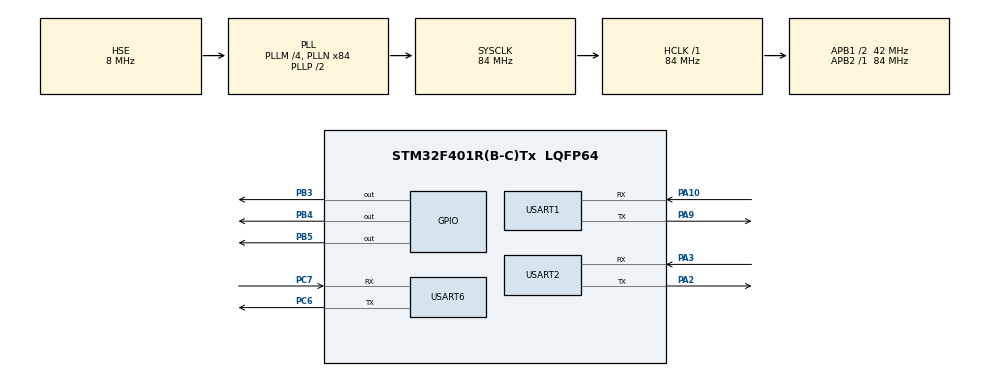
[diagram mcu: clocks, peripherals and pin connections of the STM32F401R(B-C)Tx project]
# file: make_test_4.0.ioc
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Dma.Request0=USART2_RX
Dma.Request1=USART2_TX
Dma.Request2=USART1_RX
Dma.Request3=USART1_TX
Dma.Request4=USART6_RX
Dma.Request5=USART6_TX
Dma.USART1_RX.2.Direction=DMA_PERIPH_TO_MEMORY
Dma.USART1_RX.2.FIFOMode=DMA_FIFOMODE_DISABLE
Dma.USART1_RX.2.Instance=DMA2_Stream2
Dma.USART1_RX.2.MemDataAlignment=DMA_MDATAALIGN_BYTE
Dma.USART1_RX.2.MemInc=DMA_MINC_ENABLE
Dma.USART1_RX.2.Mode=DMA_NORMAL
Dma.USART1_RX.2.PeriphDataAlignment=DMA_PDATAALIGN_BYTE
Dma.USART1_RX.2.PeriphInc=DMA_PINC_DISABLE
Dma.USART1_RX.2.Priority=DMA_PRIORITY_LOW
Dma.USART1_TX.3.Direction=DMA_MEMORY_TO_PERIPH
Dma.USART1_TX.3.FIFOMode=DMA_FIFOMODE_DISABLE
Dma.USART1_TX.3.Instance=DMA2_Stream7
Dma.USART1_TX.3.MemDataAlignment=DMA_MDATAALIGN_BYTE
Dma.USART1_TX.3.MemInc=DMA_MINC_ENABLE
Dma.USART1_TX.3.Mode=DMA_NORMAL
Dma.USART1_TX.3.PeriphDataAlignment=DMA_PDATAALIGN_BYTE
Dma.USART1_TX.3.PeriphInc=DMA_PINC_DISABLE
Dma.USART1_TX.3.Priority=DMA_PRIORITY_LOW
Dma.USART2_RX.0.Direction=DMA_PERIPH_TO_MEMORY
Dma.USART2_RX.0.FIFOMode=DMA_FIFOMODE_DISABLE
Dma.USART2_RX.0.Instance=DMA1_Stream5
Dma.USART2_RX.0.MemDataAlignment=DMA_MDATAALIGN_BYTE
Dma.USART2_RX.0.MemInc=DMA_MINC_ENABLE
Dma.USART2_RX.0.Mode=DMA_NORMAL
Dma.USART2_RX.0.PeriphDataAlignment=DMA_PDATAALIGN_BYTE
Dma.USART2_RX.0.PeriphInc=DMA_PINC_DISABLE
Dma.USART2_RX.0.Priority=DMA_PRIORITY_LOW
Dma.USART2_TX.1.Direction=DMA_MEMORY_TO_PERIPH
Dma.USART2_TX.1.FIFOMode=DMA_FIFOMODE_DISABLE
Dma.USART2_TX.1.Instance=DMA1_Stream6
Dma.USART2_TX.1.MemDataAlignment=DMA_MDATAALIGN_BYTE
Dma.USART2_TX.1.MemInc=DMA_MINC_ENABLE
Dma.USART2_TX.1.Mode=DMA_NORMAL
Dma.USART2_TX.1.PeriphDataAlignment=DMA_PDATAALIGN_BYTE
Dma.USART2_TX.1.PeriphInc=DMA_PINC_DISABLE
Dma.USART2_TX.1.Priority=DMA_PRIORITY_LOW
Dma.USART6_RX.4.Direction=DMA_PERIPH_TO_MEMORY
Dma.USART6_RX.4.FIFOMode=DMA_FIFOMODE_DISABLE
Dma.USART6_RX.4.Instance=DMA2_Stream1
Dma.USART6_RX.4.MemDataAlignment=DMA_MDATAALIGN_BYTE
Dma.USART6_RX.4.MemInc=DMA_MINC_ENABLE
Dma.USART6_RX.4.Mode=DMA_NORMAL
Dma.USART6_RX.4.PeriphDataAlignment=DMA_PDATAALIGN_BYTE
Dma.USART6_RX.4.PeriphInc=DMA_PINC_DISABLE
Dma.USART6_RX.4.Priority=DMA_PRIORITY_LOW
Dma.USART6_TX.5.Direction=DMA_MEMORY_TO_PERIPH
Dma.USART6_TX.5.FIFOMode=DMA_FIFOMODE_DISABLE
Dma.USART6_TX.5.Instance=DMA2_Stream6
Dma.USART6_TX.5.MemDataAlignment=DMA_MDATAALIGN_BYTE
Dma.USART6_TX.5.MemInc=DMA_MINC_ENABLE
Dma.USART6_TX.5.Mode=DMA_NORMAL
Dma.USART6_TX.5.PeriphDataAlignment=DMA_PDATAALIGN_BYTE
Dma.USART6_TX.5.PeriphInc=DMA_PINC_DISABLE
Dma.USART6_TX.5.Priority=DMA_PRIORITY_LOW
Mcu.Family=STM32F4
Mcu.Name=STM32F401R(B-C)Tx
Mcu.Package=LQFP64
NVIC.DMA1_Stream5_IRQn=true\:0\:0\:false\:false\:true\:false\:true
NVIC.DMA1_Stream6_IRQn=true\:0\:0\:false\:false\:true\:false\:true
NVIC.DMA2_Stream1_IRQn=true\:0\:0\:false\:false\:true\:false\:true
NVIC.DMA2_Stream2_IRQn=true\:0\:0\:false\:false\:true\:false\:true
NVIC.DMA2_Stream6_IRQn=true\:0\:0\:false\:false\:true\:false\:true
NVIC.DMA2_Stream7_IRQn=true\:0\:0\:false\:false\:true\:false\:true
NVIC.PriorityGroup=NVIC_PRIORITYGROUP_4
NVIC.USART1_IRQn=true\:0\:0\:false\:false\:false\:true\:true
NVIC.USART2_IRQn=true\:0\:0\:false\:false\:false\:true\:true
NVIC.USART6_IRQn=true\:0\:0\:false\:false\:false\:true\:true
PA10.Mode=Asynchronous
PA10.Signal=USART1_RX
PA2.Mode=Asynchronous
PA2.Signal=USART2_TX
PA3.Mode=Asynchronous
PA3.Signal=USART2_RX
PA9.Mode=Asynchronous
PA9.Signal=USART1_TX
PB3.PinState=GPIO_PIN_SET
PB3.Signal=GPIO_Output
PB4.PinState=GPIO_PIN_SET
PB4.Signal=GPIO_Output
PB5.PinState=GPIO_PIN_SET
PB5.Signal=GPIO_Output
PC14-OSC32_IN.Mode=LSE-External-Oscillator
PC14-OSC32_IN.Signal=RCC_OSC32_IN
PC15-OSC32_OUT.Mode=LSE-External-Oscillator
PC15-OSC32_OUT.Signal=RCC_OSC32_OUT
PC6.Mode=Asynchronous
PC6.Signal=USART6_TX
PC7.Mode=Asynchronous
PC7.Signal=USART6_RX
PH0\ -\ OSC_IN.Mode=HSE-External-Oscillator
PH0\ -\ OSC_IN.Signal=RCC_OSC_IN
PH1\ -\ OSC_OUT.Mode=HSE-External-Oscillator
PH1\ -\ OSC_OUT.Signal=RCC_OSC_OUT
ProjectManager.HeapSize=0x200
ProjectManager.StackSize=0x400
ProjectManager.TargetToolchain=Makefile
RCC.48MHZClocksFreq_Value=42000000
RCC.AHBFreq_Value=84000000
RCC.APB1CLKDivider=RCC_HCLK_DIV2
RCC.APB1Freq_Value=42000000
RCC.APB1TimFreq_Value=84000000
RCC.APB2Freq_Value=84000000
RCC.APB2TimFreq_Value=84000000
RCC.CortexFreq_Value=84000000
RCC.HCLKFreq_Value=84000000
RCC.HSE_VALUE=8000000
RCC.HSI_VALUE=16000000
RCC.PLLM=4
RCC.PLLN=84
RCC.PLLSourceVirtual=RCC_PLLSOURCE_HSE
RCC.SYSCLKFreq_VALUE=84000000
RCC.SYSCLKSource=RCC_SYSCLKSOURCE_PLLCLK
RCC.VCOOutputFreq_Value=168000000
USART1.VirtualMode=VM_ASYNC
USART2.VirtualMode=VM_ASYNC
USART6.VirtualMode=VM_ASYNC
board=custom

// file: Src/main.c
/* USER CODE BEGIN Header */
/**
  ******************************************************************************
  * @file           : main.c
  * @brief          : Main program body
  ******************************************************************************
  * @attention
  *
  * <h2><center>&copy; Copyright (c) 2019 STMicroelectronics.
  * All rights reserved.</center></h2>
  *
  * This software component is licensed by ST under BSD 3-Clause license,
  * the "License"; You may not use this file except in compliance with the
  * License. You may obtain a copy of the License at:
  *                        opensource.org/licenses/BSD-3-Clause
  *
  ******************************************************************************
  */
/* USER CODE END Header */

#include "main.h"

/* USER CODE BEGIN Includes */
#include "RTE_Components.h"
#include  CMSIS_device_header
#include "cmsis_os2.h"

#ifdef RTE_Compiler_EventRecorder
#include "EventRecorder.h"
#endif
/* USER CODE END Includes */

UART_HandleTypeDef huart1;
UART_HandleTypeDef huart2;
UART_HandleTypeDef huart6;
DMA_HandleTypeDef hdma_usart1_rx;
DMA_HandleTypeDef hdma_usart1_tx;
DMA_HandleTypeDef hdma_usart2_rx;
DMA_HandleTypeDef hdma_usart2_tx;
DMA_HandleTypeDef hdma_usart6_rx;
DMA_HandleTypeDef hdma_usart6_tx;

void SystemClock_Config(void);
static void MX_GPIO_Init(void);
static void MX_DMA_Init(void);
static void MX_USART1_UART_Init(void);
static void MX_USART2_UART_Init(void);
static void MX_USART6_UART_Init(void);

/* USER CODE BEGIN 0 */
uint32_t HAL_GetTick(void)
{
  return osKernelGetTickCount();
}
void app_main (void *argument) {

  // ...
  for (;;) {
    HAL_GPIO_TogglePin(GPIOA, GPIO_PIN_8);
    osDelay(50);
  }
}
/* USER CODE END 0 */

static osThreadId_t user_id = NULL;
int main(void)
{

  /* MCU Configuration--------------------------------------------------------*/

  /* Reset of all peripherals, Initializes the Flash interface and the Systick. */
  HAL_Init();

  /* Configure the system clock */
  SystemClock_Config();

  /* Initialize all configured peripherals */
  MX_GPIO_Init();
  MX_DMA_Init();
  MX_USART1_UART_Init();
  MX_USART2_UART_Init();
  MX_USART6_UART_Init();
  /* USER CODE BEGIN 2 */
  SystemCoreClockUpdate();
#ifdef RTE_Compiler_EventRecorder
  // Initialize and start Event Recorder
  EventRecorderInitialize(EventRecordError, 1U);
#endif
  // ...
  const osThreadAttr_t attr = {
    .stack_size = 512
  };
  osKernelInitialize();                 // Initialize CMSIS-RTOS
  user_id = osThreadNew(app_main, NULL, &attr);    // Create application main thread

  osKernelStart();
  /* USER CODE END 2 */

  /* Infinite loop */
  while (1)
  {

  }
}

void SystemClock_Config(void)
{
  RCC_OscInitTypeDef RCC_OscInitStruct = {0};
  RCC_ClkInitTypeDef RCC_ClkInitStruct = {0};

  /** Configure the main internal regulator output voltage
  */
  __HAL_RCC_PWR_CLK_ENABLE();
  __HAL_PWR_VOLTAGESCALING_CONFIG(PWR_REGULATOR_VOLTAGE_SCALE2);
  /** Initializes the CPU, AHB and APB busses clocks
  */
  RCC_OscInitStruct.OscillatorType = RCC_OSCILLATORTYPE_HSE;
  RCC_OscInitStruct.HSEState = RCC_HSE_ON;
  RCC_OscInitStruct.PLL.PLLState = RCC_PLL_ON;
  RCC_OscInitStruct.PLL.PLLSource = RCC_PLLSOURCE_HSE;
  RCC_OscInitStruct.PLL.PLLM = 4;
  RCC_OscInitStruct.PLL.PLLN = 84;
  RCC_OscInitStruct.PLL.PLLP = RCC_PLLP_DIV2;
  RCC_OscInitStruct.PLL.PLLQ = 4;
  if (HAL_RCC_OscConfig(&RCC_OscInitStruct) != HAL_OK)
  {
    Error_Handler();
  }
  /** Initializes the CPU, AHB and APB busses clocks
  */
  RCC_ClkInitStruct.ClockType = RCC_CLOCKTYPE_HCLK|RCC_CLOCKTYPE_SYSCLK
                              |RCC_CLOCKTYPE_PCLK1|RCC_CLOCKTYPE_PCLK2;
  RCC_ClkInitStruct.SYSCLKSource = RCC_SYSCLKSOURCE_PLLCLK;
  RCC_ClkInitStruct.AHBCLKDivider = RCC_SYSCLK_DIV1;
  RCC_ClkInitStruct.APB1CLKDivider = RCC_HCLK_DIV2;
  RCC_ClkInitStruct.APB2CLKDivider = RCC_HCLK_DIV1;

  if (HAL_RCC_ClockConfig(&RCC_ClkInitStruct, FLASH_LATENCY_2) != HAL_OK)
  {
    Error_Handler();
  }
}

static void MX_USART1_UART_Init(void)
{

  huart1.Instance = USART1;
  huart1.Init.BaudRate = 115200;
  huart1.Init.WordLength = UART_WORDLENGTH_8B;
  huart1.Init.StopBits = UART_STOPBITS_1;
  huart1.Init.Parity = UART_PARITY_NONE;
  huart1.Init.Mode = UART_MODE_TX_RX;
  huart1.Init.HwFlowCtl = UART_HWCONTROL_NONE;
  huart1.Init.OverSampling = UART_OVERSAMPLING_16;
  if (HAL_UART_Init(&huart1) != HAL_OK)
  {
    Error_Handler();
  }

}

static void MX_USART2_UART_Init(void)
{

  huart2.Instance = USART2;
  huart2.Init.BaudRate = 115200;
  huart2.Init.WordLength = UART_WORDLENGTH_8B;
  huart2.Init.StopBits = UART_STOPBITS_1;
  huart2.Init.Parity = UART_PARITY_NONE;
  huart2.Init.Mode = UART_MODE_TX_RX;
  huart2.Init.HwFlowCtl = UART_HWCONTROL_NONE;
  huart2.Init.OverSampling = UART_OVERSAMPLING_16;
  if (HAL_UART_Init(&huart2) != HAL_OK)
  {
    Error_Handler();
  }

}

static void MX_USART6_UART_Init(void)
{

  huart6.Instance = USART6;
  huart6.Init.BaudRate = 115200;
  huart6.Init.WordLength = UART_WORDLENGTH_8B;
  huart6.Init.StopBits = UART_STOPBITS_1;
  huart6.Init.Parity = UART_PARITY_NONE;
  huart6.Init.Mode = UART_MODE_TX_RX;
  huart6.Init.HwFlowCtl = UART_HWCONTROL_NONE;
  huart6.Init.OverSampling = UART_OVERSAMPLING_16;
  if (HAL_UART_Init(&huart6) != HAL_OK)
  {
    Error_Handler();
  }

}

static void MX_DMA_Init(void)
{
  /* DMA controller clock enable */
  __HAL_RCC_DMA1_CLK_ENABLE();
  __HAL_RCC_DMA2_CLK_ENABLE();

  /* DMA interrupt init */
  /* DMA1_Stream5_IRQn interrupt configuration */
  HAL_NVIC_SetPriority(DMA1_Stream5_IRQn, 0, 0);
  HAL_NVIC_EnableIRQ(DMA1_Stream5_IRQn);
  /* DMA1_Stream6_IRQn interrupt configuration */
  HAL_NVIC_SetPriority(DMA1_Stream6_IRQn, 0, 0);
  HAL_NVIC_EnableIRQ(DMA1_Stream6_IRQn);
  /* DMA2_Stream1_IRQn interrupt configuration */
  HAL_NVIC_SetPriority(DMA2_Stream1_IRQn, 0, 0);
  HAL_NVIC_EnableIRQ(DMA2_Stream1_IRQn);
  /* DMA2_Stream2_IRQn interrupt configuration */
  HAL_NVIC_SetPriority(DMA2_Stream2_IRQn, 0, 0);
  HAL_NVIC_EnableIRQ(DMA2_Stream2_IRQn);
  /* DMA2_Stream6_IRQn interrupt configuration */
  HAL_NVIC_SetPriority(DMA2_Stream6_IRQn, 0, 0);
  HAL_NVIC_EnableIRQ(DMA2_Stream6_IRQn);
  /* DMA2_Stream7_IRQn interrupt configuration */
  HAL_NVIC_SetPriority(DMA2_Stream7_IRQn, 0, 0);
  HAL_NVIC_EnableIRQ(DMA2_Stream7_IRQn);

}

static void MX_GPIO_Init(void)
{
  GPIO_InitTypeDef GPIO_InitStruct = {0};

  /* GPIO Ports Clock Enable */
  __HAL_RCC_GPIOC_CLK_ENABLE();
  __HAL_RCC_GPIOH_CLK_ENABLE();
  __HAL_RCC_GPIOA_CLK_ENABLE();
  __HAL_RCC_GPIOB_CLK_ENABLE();

  /*Configure GPIO pin Output Level */
  HAL_GPIO_WritePin(GPIOA, GPIO_PIN_8, GPIO_PIN_SET);

  /*Configure GPIO pins : PB3 PB4 PB5 */
  GPIO_InitStruct.Pin = GPIO_PIN_8;
  GPIO_InitStruct.Mode = GPIO_MODE_OUTPUT_PP;
  GPIO_InitStruct.Pull = GPIO_NOPULL;
  GPIO_InitStruct.Speed = GPIO_SPEED_FREQ_LOW;
  HAL_GPIO_Init(GPIOA, &GPIO_InitStruct);

}

void Error_Handler(void)
{
}

/************************ (C) COPYRIGHT STMicroelectronics *****END OF FILE****/
